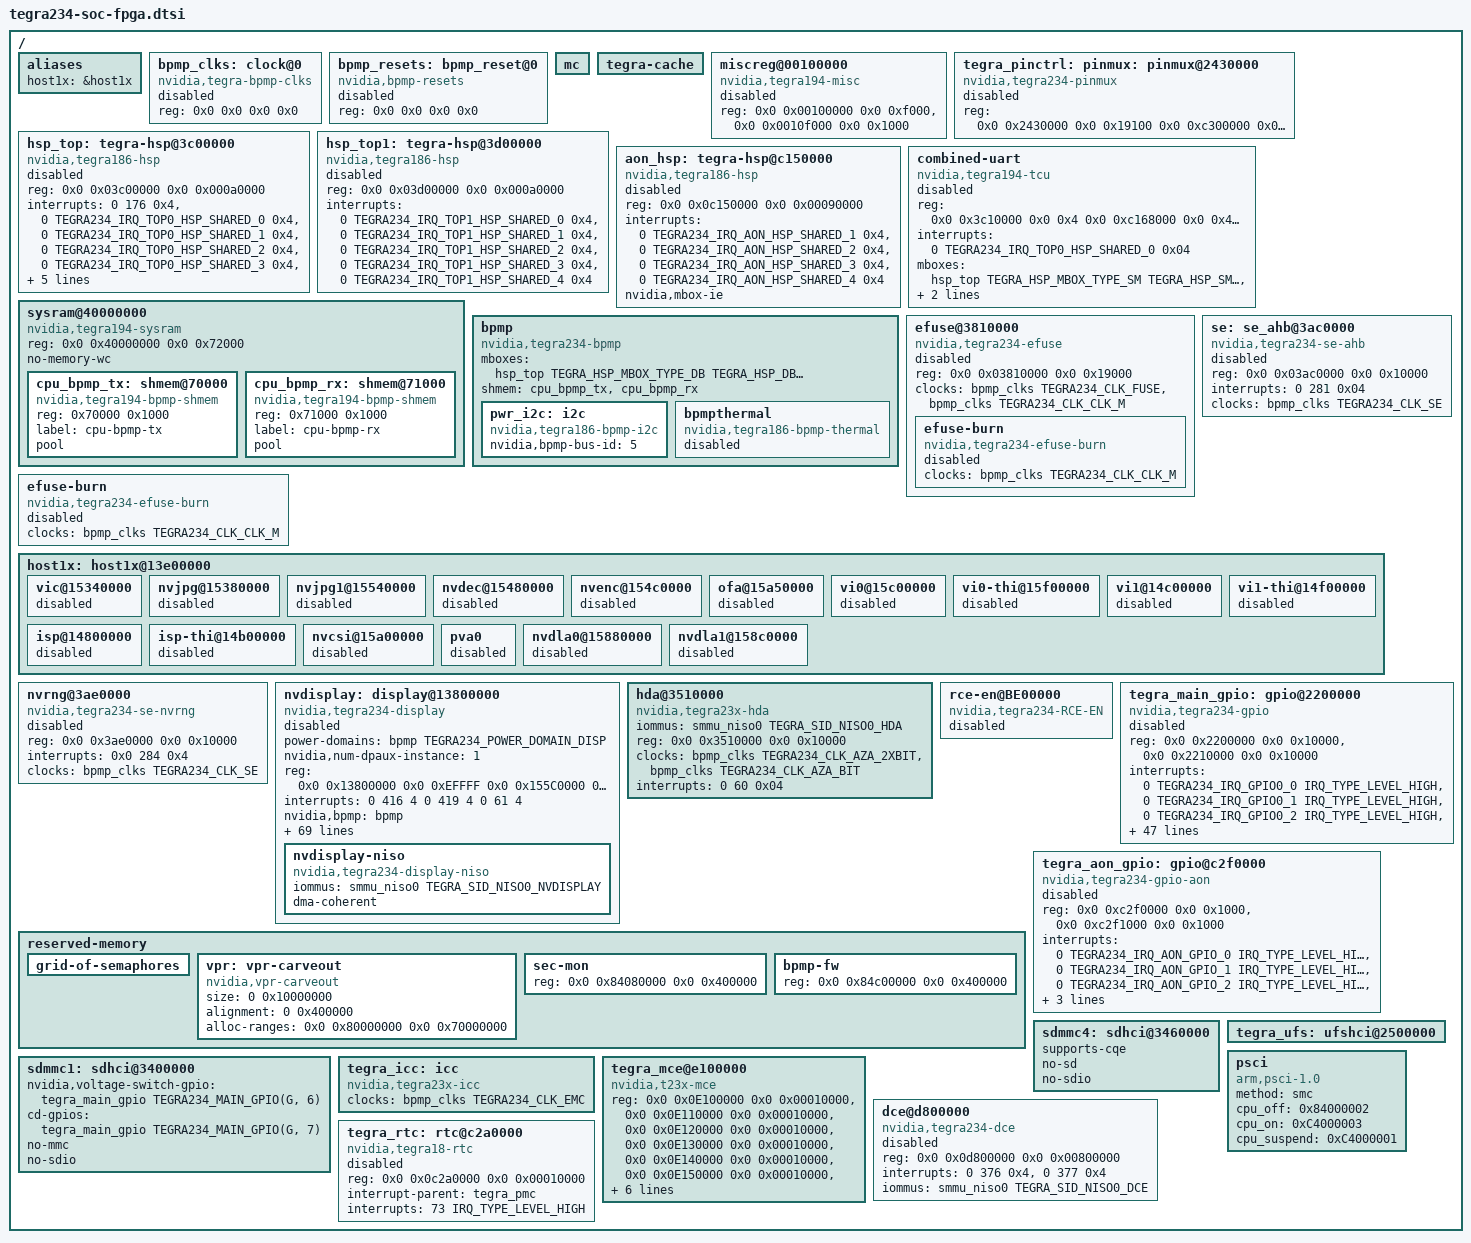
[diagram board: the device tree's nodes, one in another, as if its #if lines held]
/*
 * Copyright (c) 2019-2022, NVIDIA CORPORATION.  All rights reserved.
 *
 * This program is free software; you can redistribute it and/or modify it
 * under the terms and conditions of the GNU General Public License,
 * version 2, as published by the Free Software Foundation.
 *
 * This program is distributed in the hope it will be useful, but WITHOUT
 * ANY WARRANTY; without even the implied warranty of MERCHANTABILITY or
 * FITNESS FOR A PARTICULAR PURPOSE.  See the GNU General Public License for
 * more details.
 *
 * You should have received a copy of the GNU General Public License
 * along with this program.  If not, see <http://www.gnu.org/licenses/>.
 */

#include "tegra234-soc/tegra234-soc-minimal.dtsi"
#include <dt-bindings/memory/tegra234-smmu-streamid.h>
#include "tegra234-soc-cbb.dtsi"
#include "tegra234-soc/tegra234-soc-memory.dtsi"
#include "tegra234-soc-pcie-fpga.dtsi"
#include <dt-bindings/gpio/tegra234-gpio.h>
#include <dt-bindings/mailbox/tegra186-hsp.h>
#include "tegra234-soc-gpcdma.dtsi"
#include <dt-bindings/clock/tegra234-clock.h>
#include <dt-bindings/clock/tegra194-clock.h>
#include <dt-bindings/reset/tegra234-reset.h>
#include "dt-bindings/soc/tegra234-powergate.h"
#include "tegra234-soc/tegra234-soc-sdhci.dtsi"
#include "tegra234-soc-pmc.dtsi"
#include "tegra234-soc-uart.dtsi"
#include "tegra234-soc-i2c.dtsi"
#include "tegra234-soc-ufshc.dtsi"
#include "tegra234-soc-spi.dtsi"
#include "tegra234-psc.dtsi"
#include "tegra234-soc-host1x.dtsi"
#include "tegra234-aon.dtsi"
#include "tegra234-soc-coresight.dtsi"
#include <dt-bindings/interconnect/tegra_icc_id.h>

/ {
	aliases {
		host1x = &host1x;
	};

#if TEGRA_BPMP_FW_DT_VERSION <= DT_VERSION_1
	bpmp_clks: clock@0 {
		compatible = "nvidia,tegra-bpmp-clks";
		reg = <0x0 0x0 0x0 0x0>;
		#clock-cells = <1>;
		status = "disabled";
	};

	bpmp_resets: bpmp_reset@0 {
		compatible = "nvidia,bpmp-resets";
		reg = <0x0 0x0 0x0 0x0>;
		#reset-cells = <1>;
		status = "disabled";
	};
#endif

	mc {
		status = "okay";
	};

	/* L4 cache */
	tegra-cache {
		status = "okay";
	};

	miscreg@00100000 {
		compatible = "nvidia,tegra194-misc", "nvidia,tegra186-miscreg";
		reg = <0x0 0x00100000 0x0 0xf000>, /* Chipid */
		      <0x0 0x0010f000 0x0 0x1000>; /* Straps */
		status = "disabled";
	};

	tegra_pinctrl: pinmux: pinmux@2430000 {
		compatible = "nvidia,tegra234-pinmux";
		reg = <0x0 0x2430000 0x0 0x19100
			0x0 0xc300000 0x0 0x4000>;
		#gpio-range-cells = <3>;
		status = "disabled";
	};

	hsp_top: tegra-hsp@3c00000 {
		compatible = "nvidia,tegra186-hsp";
		reg = <0x0 0x03c00000 0x0 0x000a0000>;
		interrupts =	<0 176 0x4>,
				<0 TEGRA234_IRQ_TOP0_HSP_SHARED_0 0x4>,
				<0 TEGRA234_IRQ_TOP0_HSP_SHARED_1 0x4>,
				<0 TEGRA234_IRQ_TOP0_HSP_SHARED_2 0x4>,
				<0 TEGRA234_IRQ_TOP0_HSP_SHARED_3 0x4>,
				<0 TEGRA234_IRQ_TOP0_HSP_SHARED_4 0x4>,
				<0 TEGRA234_IRQ_TOP0_HSP_SHARED_5 0x4>,
				<0 TEGRA234_IRQ_TOP0_HSP_SHARED_6 0x4>,
				<0 TEGRA234_IRQ_TOP0_HSP_SHARED_7 0x4>;
		interrupt-names = "doorbell",
				"shared0", "shared1", "shared2", "shared3",
				"shared4", "shared5", "shared6", "shared7";
		#mbox-cells = <2>;
		nvidia,mbox-ie;
		status = "disabled";
	};

	hsp_top1: tegra-hsp@3d00000 {
		compatible = "nvidia,tegra186-hsp";
		reg = <0x0 0x03d00000 0x0 0x000a0000>;
		interrupts = <0 TEGRA234_IRQ_TOP1_HSP_SHARED_0 0x4>,
				<0 TEGRA234_IRQ_TOP1_HSP_SHARED_1 0x4>,
				<0 TEGRA234_IRQ_TOP1_HSP_SHARED_2 0x4>,
				<0 TEGRA234_IRQ_TOP1_HSP_SHARED_3 0x4>,
				<0 TEGRA234_IRQ_TOP1_HSP_SHARED_4 0x4>;
		interrupt-names = "shared0", "shared1", "shared2", "shared3", "shared4";
		#mbox-cells = <2>;
		status = "disabled";
	};

    aon_hsp: tegra-hsp@c150000 {
        compatible = "nvidia,tegra186-hsp";
        reg = <0x0 0x0c150000 0x0 0x00090000>;
        interrupts = <0 TEGRA234_IRQ_AON_HSP_SHARED_1 0x4>,
                <0 TEGRA234_IRQ_AON_HSP_SHARED_2 0x4>,
                <0 TEGRA234_IRQ_AON_HSP_SHARED_3 0x4>,
                <0 TEGRA234_IRQ_AON_HSP_SHARED_4 0x4>;
        interrupt-names = "shared1", "shared2", "shared3", "shared4";
        #mbox-cells = <2>;
        nvidia,mbox-ie;
        status = "disabled";
    };

    combined-uart {
        compatible = "nvidia,tegra194-tcu";
        reg = <0x0 0x3c10000 0x0 0x4   /* TOP0_HSP_SM_0_1_BASE */
               0x0 0xc168000 0x0 0x4       /* AON_HSP_SM_1_BASE */
               0x0 0x3c00000 0x0 0x1000>; /* TOP0_HSP_COMMON_BASE */
        interrupts = <0 TEGRA234_IRQ_TOP0_HSP_SHARED_0 0x04>;
        mboxes = <&hsp_top TEGRA_HSP_MBOX_TYPE_SM TEGRA_HSP_SM_RX(0)>,
            <&aon_hsp TEGRA_HSP_MBOX_TYPE_SM TEGRA_HSP_SM_TX(1)>;
        mbox-names = "rx", "tx";
        status = "disabled";
    };

#if TEGRA_BPMP_FW_DT_VERSION >= DT_VERSION_2
	sysram@40000000 {
		compatible = "nvidia,tegra194-sysram", "mmio-sram";
		reg = <0x0 0x40000000 0x0 0x72000>;
		#address-cells = <1>;
		#size-cells = <1>;
		ranges = <0x0 0x0 0x40000000 0x72000>;
		no-memory-wc;

		cpu_bpmp_tx: shmem@70000 {
			compatible = "nvidia,tegra194-bpmp-shmem";
			reg = <0x70000 0x1000>;
			label = "cpu-bpmp-tx";
			pool;
		};

		cpu_bpmp_rx: shmem@71000 {
			compatible = "nvidia,tegra194-bpmp-shmem";
			reg = <0x71000 0x1000>;
			label = "cpu-bpmp-rx";
			pool;
		};
	};

	bpmp: bpmp {
		compatible = "nvidia,tegra234-bpmp", "nvidia,tegra186-bpmp";
		mboxes = <&hsp_top TEGRA_HSP_MBOX_TYPE_DB
				   TEGRA_HSP_DB_MASTER_BPMP>;
		shmem = <&cpu_bpmp_tx &cpu_bpmp_rx>;
		#clock-cells = <1>;
		#reset-cells = <1>;
		#power-domain-cells = <1>;

		pwr_i2c: i2c {
			compatible = "nvidia,tegra186-bpmp-i2c";
			nvidia,bpmp-bus-id = <5>;
			#address-cells = <1>;
			#size-cells = <0>;
		};

		bpmpthermal {
			compatible = "nvidia,tegra186-bpmp-thermal";
			#thermal-sensor-cells = <1>;
			status = "disabled";
		};
	};
#else
	bpmp: bpmp {
		compatible = "nvidia,tegra186-bpmp";
		iommus = <&smmu_niso1 TEGRA_SID_NISO1_BPMP>;
		dma-coherent;
		reg = <0x0 0x0d000000 0x0 0x00800000>,
		      <0x0 0x40070000 0x0 0x00001000>,
		      <0x0 0x40071000 0x0 0x00001000>;
		status = "disabled";
		#power-domain-cells = <1>;
		#strap-cells = <1>;
		#nvidia,controller-id-cells = <1>;

		bpmpthermal {
			compatible = "nvidia,tegra186-bpmp-thermal";
			#thermal-sensor-cells = <1>;
			status = "disabled";
		};
	};
#endif

	efuse@3810000 {
		compatible = "nvidia,tegra234-efuse";
		reg = <0x0 0x03810000 0x0 0x19000>;
		clocks = <&bpmp_clks TEGRA234_CLK_FUSE>,
		         <&bpmp_clks TEGRA234_CLK_CLK_M>;
		clock-names = "fuse", "clk_m";
		status = "disabled";
#if LINUX_VERSION < 419
		efuse-burn {
			compatible = "nvidia,tegra234-efuse-burn";
			clocks = <&bpmp_clks TEGRA234_CLK_CLK_M>;
			clock-names = "clk_m";
			status = "disabled";
		};
#endif
	};
#if LINUX_VERSION >= 419
	efuse-burn {
		compatible = "nvidia,tegra234-efuse-burn";
		clocks = <&bpmp_clks TEGRA234_CLK_CLK_M>;
		clock-names = "clk_m";
		status = "disabled";
	};
#endif

	se: se_ahb@3ac0000 {
		compatible = "nvidia,tegra234-se-ahb";
		reg = <0x0 0x03ac0000 0x0 0x10000>;
		interrupts = <0 281 0x04>;
		clocks = <&bpmp_clks TEGRA234_CLK_SE>;
		clock-names = "se";
		status = "disabled";
	};

	host1x: host1x@13e00000 {

		vic@15340000 {
			status = "disabled";
		};

		nvjpg@15380000 {
			status = "disabled";
		};

		nvjpg1@15540000 {
			status = "disabled";
		};

		nvdec@15480000 {
			status = "disabled";
		};

		nvenc@154c0000 {
			status = "disabled";
		};

		ofa@15a50000 {
			status = "disabled";
		};

		vi0@15c00000 {
			status = "disabled";
		};

		vi0-thi@15f00000 {
			status = "disabled";
		};

		vi1@14c00000 {
			status = "disabled";
		};

		vi1-thi@14f00000 {
			status = "disabled";
		};

		isp@14800000 {
			status = "disabled";
		};

		isp-thi@14b00000 {
			status = "disabled";
		};

		nvcsi@15a00000 {
			status = "disabled";
		};

		pva0 {
			status = "disabled";
		};

		nvdla0@15880000 {
			status = "disabled";
		};

		nvdla1@158c0000 {
			status = "disabled";
		};
	};

	nvrng@3ae0000 {
		compatible = "nvidia,tegra234-se-nvrng";
		reg = <0x0 0x3ae0000 0x0 0x10000>;
		interrupts = <0x0 284 0x4>;
		clocks = <&bpmp_clks TEGRA234_CLK_SE>;
		clock-names = "se";
		status = "disabled";
	};

	nvdisplay: display@13800000 {
		compatible = "nvidia,tegra234-display";
		power-domains = <&bpmp TEGRA234_POWER_DOMAIN_DISP>;
		nvidia,num-dpaux-instance = <1>;
		reg-names = "nvdisplay", "dpaux0", "hdacodec";
		reg = <0x0 0x13800000 0x0 0xEFFFF    /* nvdisplay */
		       0x0 0x155C0000 0x0 0xFFFF     /* dpaux0 */
		       0x0 0x0242c000 0x0 0x1000>;   /* hdacodec */
		interrupt-names = "nvdisplay", "dpaux0", "hdacodec";
		interrupts = <0 416 4
			      0 419 4
			      0  61 4>;
		nvidia,bpmp = <&bpmp>;
		clocks = <&bpmp_clks TEGRA234_CLK_HUB>,
			 <&bpmp_clks TEGRA234_CLK_DISP>,
			 <&bpmp_clks TEGRA234_CLK_NVDISPLAY_P0>,
			 <&bpmp_clks TEGRA234_CLK_NVDISPLAY_P1>,
			 <&bpmp_clks TEGRA234_CLK_DPAUX>,
			 <&bpmp_clks TEGRA234_CLK_FUSE>,
			 <&bpmp_clks TEGRA234_CLK_DSIPLL_VCO>,
			 <&bpmp_clks TEGRA234_CLK_DSIPLL_CLKOUTPN>,
			 <&bpmp_clks TEGRA234_CLK_DSIPLL_CLKOUTA>,
			 <&bpmp_clks TEGRA234_CLK_SPPLL0_VCO>,
			 <&bpmp_clks TEGRA234_CLK_SPPLL0_CLKOUTPN>,
			 <&bpmp_clks TEGRA234_CLK_SPPLL0_CLKOUTA>,
			 <&bpmp_clks TEGRA234_CLK_SPPLL0_CLKOUTB>,
			 <&bpmp_clks TEGRA234_CLK_SPPLL0_DIV10>,
			 <&bpmp_clks TEGRA234_CLK_SPPLL0_DIV25>,
			 <&bpmp_clks TEGRA234_CLK_SPPLL0_DIV27PN>,
			 <&bpmp_clks TEGRA234_CLK_SPPLL1_VCO>,
			 <&bpmp_clks TEGRA234_CLK_SPPLL1_CLKOUTPN>,
			 <&bpmp_clks TEGRA234_CLK_SPPLL1_DIV27PN>,
			 <&bpmp_clks TEGRA234_CLK_VPLL0_REF>,
			 <&bpmp_clks TEGRA234_CLK_VPLL0>,
			 <&bpmp_clks TEGRA234_CLK_VPLL1>,
			 <&bpmp_clks TEGRA234_CLK_NVDISPLAY_P0_REF>,
			 <&bpmp_clks TEGRA234_CLK_RG0>,
			 <&bpmp_clks TEGRA234_CLK_RG1>,
			 <&bpmp_clks TEGRA234_CLK_DISPPLL>,
			 <&bpmp_clks TEGRA234_CLK_DISPHUBPLL>,
			 <&bpmp_clks TEGRA234_CLK_DSI_LP>,
			 <&bpmp_clks TEGRA234_CLK_DSI_CORE>,
			 <&bpmp_clks TEGRA234_CLK_DSI_PIXEL>,
			 <&bpmp_clks TEGRA234_CLK_PRE_SOR0>,
			 <&bpmp_clks TEGRA234_CLK_PRE_SOR1>,
			 <&bpmp_clks TEGRA234_CLK_DP_LINK_REF>,
			 <&bpmp_clks TEGRA234_CLK_SOR_LINKA_INPUT>,
			 <&bpmp_clks TEGRA234_CLK_SOR_LINKA_AFIFO>,
			 <&bpmp_clks TEGRA234_CLK_SOR_LINKA_AFIFO_M>,
			 <&bpmp_clks TEGRA234_CLK_RG0_M>,
			 <&bpmp_clks TEGRA234_CLK_RG1_M>,
			 <&bpmp_clks TEGRA234_CLK_SOR0_M>,
			 <&bpmp_clks TEGRA234_CLK_SOR1_M>,
			 <&bpmp_clks TEGRA234_CLK_PLLHUB>,
			 <&bpmp_clks TEGRA234_CLK_SOR0>,
			 <&bpmp_clks TEGRA234_CLK_SOR1>,
			 <&bpmp_clks TEGRA234_CLK_SOR_PAD_INPUT>,
			 <&bpmp_clks TEGRA234_CLK_PRE_SF0>,
			 <&bpmp_clks TEGRA234_CLK_SF0>,
			 <&bpmp_clks TEGRA234_CLK_SF1>,
			 <&bpmp_clks TEGRA234_CLK_DSI_PAD_INPUT>,
			 <&bpmp_clks TEGRA234_CLK_PRE_SOR0_REF>,
			 <&bpmp_clks TEGRA234_CLK_PRE_SOR1_REF>,
			 <&bpmp_clks TEGRA234_CLK_SOR0_PLL_REF>,
			 <&bpmp_clks TEGRA234_CLK_SOR1_PLL_REF>,
			 <&bpmp_clks TEGRA234_CLK_SOR0_REF>,
			 <&bpmp_clks TEGRA234_CLK_SOR1_REF>,
			 <&bpmp_clks TEGRA234_CLK_OSC>,
			 <&bpmp_clks TEGRA234_CLK_DSC>,
			 <&bpmp_clks TEGRA234_CLK_MAUD>,
			 <&bpmp_clks TEGRA234_CLK_AZA_2XBIT>,
			 <&bpmp_clks TEGRA234_CLK_AZA_BIT>,
			 <&bpmp_clks TEGRA234_CLK_MIPI_CAL>,
			 <&bpmp_clks TEGRA234_CLK_UART_FST_MIPI_CAL>,
			 <&bpmp_clks TEGRA234_CLK_SOR0_DIV>;
		clock-names = "nvdisplayhub_clk",
			      "nvdisplay_disp_clk",
			      "nvdisplay_p0_clk",
			      "nvdisplay_p1_clk",
			      "dpaux0_clk",
			      "fuse_clk",
			      "dsipll_vco_clk",
			      "dsipll_clkoutpn_clk",
			      "dsipll_clkouta_clk",
			      "sppll0_vco_clk",
			      "sppll0_clkoutpn_clk",
			      "sppll0_clkouta_clk",
			      "sppll0_clkoutb_clk",
			      "sppll0_div10_clk",
			      "sppll0_div25_clk",
			      "sppll0_div27_clk",
			      "sppll1_vco_clk",
			      "sppll1_clkoutpn_clk",
			      "sppll1_div27_clk",
			      "vpll0_ref_clk",
			      "vpll0_clk",
			      "vpll1_clk",
			      "nvdisplay_p0_ref_clk",
			      "rg0_clk",
			      "rg1_clk",
			      "disppll_clk",
			      "disphubpll_clk",
			      "dsi_lp_clk",
			      "dsi_core_clk",
			      "dsi_pixel_clk",
			      "pre_sor0_clk",
			      "pre_sor1_clk",
			      "dp_link_ref_clk",
			      "sor_linka_input_clk",
			      "sor_linka_afifo_clk",
			      "sor_linka_afifo_m_clk",
			      "rg0_m_clk",
			      "rg1_m_clk",
			      "sor0_m_clk",
			      "sor1_m_clk",
			      "pllhub_clk",
			      "sor0_clk",
			      "sor1_clk",
			      "sor_pad_input_clk",
			      "pre_sf0_clk",
			      "sf0_clk",
			      "sf1_clk",
			      "dsi_pad_input_clk",
			      "pre_sor0_ref_clk",
			      "pre_sor1_ref_clk",
			      "sor0_ref_pll_clk",
			      "sor1_ref_pll_clk",
			      "sor0_ref_clk",
			      "sor1_ref_clk",
			      "osc_clk",
			      "dsc_clk",
			      "maud_clk",
			      "aza_2xbit_clk",
			      "aza_bit_clk",
			      "mipi_cal_clk",
			      "uart_fst_mipi_cal_clk",
			      "sor0_div_clk";
		resets = <&bpmp_resets TEGRA234_RESET_NVDISPLAY>,
			 <&bpmp_resets TEGRA234_RESET_DPAUX>,
			 <&bpmp_resets TEGRA234_RESET_HDACODEC>,
			 <&bpmp_resets TEGRA234_RESET_DSI_CORE>,
			 <&bpmp_resets TEGRA234_RESET_MIPI_CAL>;
		reset-names = "nvdisplay_reset",
			      "dpaux0_reset",
			      "hdacodec_reset",
			      "dsi_core_reset",
			      "mipi_cal_reset";
		status = "disabled";
		iommus = <&smmu_iso TEGRA_SID_ISO_NVDISPLAY>;
		non-coherent;
		nvdisplay-niso {
			compatible = "nvidia,tegra234-display-niso";
			iommus = <&smmu_niso0 TEGRA_SID_NISO0_NVDISPLAY>;
			dma-coherent;
		};
	};

        hda@3510000 {
                compatible = "nvidia,tegra23x-hda";
                iommus = <&smmu_niso0 TEGRA_SID_NISO0_HDA>;
                reg = <0x0 0x3510000 0x0 0x10000>;
                clocks = <&bpmp_clks TEGRA234_CLK_AZA_2XBIT>,
                         <&bpmp_clks TEGRA234_CLK_AZA_BIT>;
		clock-names = "hda", "hda2codec_2x";
                interrupts = <0 60 0x04>;
                status = "okay";
        };

	rce-en@BE00000 {
		compatible = "nvidia,tegra234-RCE-EN";
		status = "disabled";
	};

        reserved-memory {
                grid-of-semaphores {
                        /delete-property/ cvdevs;
                };

		vpr: vpr-carveout {
				compatible = "nvidia,vpr-carveout";
				size = <0 0x10000000>;
				alignment = <0 0x400000>;
				alloc-ranges = <0x0 0x80000000 0x0 0x70000000>;
		};

		/* The sec-mon memory in bootwrapper */
		sec-mon {
			reg = <0x0 0x84080000 0x0 0x400000>;
		};

		bpmp-fw {
                        reg = <0x0 0x84c00000 0x0 0x400000>;
                };
        };

	tegra_main_gpio: gpio@2200000 {
		compatible = "nvidia,tegra234-gpio";
		reg-names = "security", "gpio";
		reg =	<0x0 0x2200000 0x0 0x10000>,
			<0x0 0x2210000 0x0 0x10000>;
		interrupts =
			<0 TEGRA234_IRQ_GPIO0_0 IRQ_TYPE_LEVEL_HIGH>,
			<0 TEGRA234_IRQ_GPIO0_1 IRQ_TYPE_LEVEL_HIGH>,
			<0 TEGRA234_IRQ_GPIO0_2 IRQ_TYPE_LEVEL_HIGH>,
			<0 TEGRA234_IRQ_GPIO0_3 IRQ_TYPE_LEVEL_HIGH>,
			<0 TEGRA234_IRQ_GPIO0_4 IRQ_TYPE_LEVEL_HIGH>,
			<0 TEGRA234_IRQ_GPIO0_5 IRQ_TYPE_LEVEL_HIGH>,
			<0 TEGRA234_IRQ_GPIO0_6 IRQ_TYPE_LEVEL_HIGH>,
			<0 TEGRA234_IRQ_GPIO0_7 IRQ_TYPE_LEVEL_HIGH>,
			<0 TEGRA234_IRQ_GPIO1_0 IRQ_TYPE_LEVEL_HIGH>,
			<0 TEGRA234_IRQ_GPIO1_1 IRQ_TYPE_LEVEL_HIGH>,
			<0 TEGRA234_IRQ_GPIO1_2 IRQ_TYPE_LEVEL_HIGH>,
			<0 TEGRA234_IRQ_GPIO1_3 IRQ_TYPE_LEVEL_HIGH>,
			<0 TEGRA234_IRQ_GPIO1_4 IRQ_TYPE_LEVEL_HIGH>,
			<0 TEGRA234_IRQ_GPIO1_5 IRQ_TYPE_LEVEL_HIGH>,
			<0 TEGRA234_IRQ_GPIO1_6 IRQ_TYPE_LEVEL_HIGH>,
			<0 TEGRA234_IRQ_GPIO1_7 IRQ_TYPE_LEVEL_HIGH>,
			<0 TEGRA234_IRQ_GPIO2_0 IRQ_TYPE_LEVEL_HIGH>,
			<0 TEGRA234_IRQ_GPIO2_1 IRQ_TYPE_LEVEL_HIGH>,
			<0 TEGRA234_IRQ_GPIO2_2 IRQ_TYPE_LEVEL_HIGH>,
			<0 TEGRA234_IRQ_GPIO2_3 IRQ_TYPE_LEVEL_HIGH>,
			<0 TEGRA234_IRQ_GPIO2_4 IRQ_TYPE_LEVEL_HIGH>,
			<0 TEGRA234_IRQ_GPIO2_5 IRQ_TYPE_LEVEL_HIGH>,
			<0 TEGRA234_IRQ_GPIO2_6 IRQ_TYPE_LEVEL_HIGH>,
			<0 TEGRA234_IRQ_GPIO2_7 IRQ_TYPE_LEVEL_HIGH>,
			<0 TEGRA234_IRQ_GPIO3_0 IRQ_TYPE_LEVEL_HIGH>,
			<0 TEGRA234_IRQ_GPIO3_1 IRQ_TYPE_LEVEL_HIGH>,
			<0 TEGRA234_IRQ_GPIO3_2 IRQ_TYPE_LEVEL_HIGH>,
			<0 TEGRA234_IRQ_GPIO3_3 IRQ_TYPE_LEVEL_HIGH>,
			<0 TEGRA234_IRQ_GPIO3_4 IRQ_TYPE_LEVEL_HIGH>,
			<0 TEGRA234_IRQ_GPIO3_5 IRQ_TYPE_LEVEL_HIGH>,
			<0 TEGRA234_IRQ_GPIO3_6 IRQ_TYPE_LEVEL_HIGH>,
			<0 TEGRA234_IRQ_GPIO3_7 IRQ_TYPE_LEVEL_HIGH>,
			<0 TEGRA234_IRQ_GPIO4_0 IRQ_TYPE_LEVEL_HIGH>,
			<0 TEGRA234_IRQ_GPIO4_1 IRQ_TYPE_LEVEL_HIGH>,
			<0 TEGRA234_IRQ_GPIO4_2 IRQ_TYPE_LEVEL_HIGH>,
			<0 TEGRA234_IRQ_GPIO4_3 IRQ_TYPE_LEVEL_HIGH>,
			<0 TEGRA234_IRQ_GPIO4_4 IRQ_TYPE_LEVEL_HIGH>,
			<0 TEGRA234_IRQ_GPIO4_5 IRQ_TYPE_LEVEL_HIGH>,
			<0 TEGRA234_IRQ_GPIO4_6 IRQ_TYPE_LEVEL_HIGH>,
			<0 TEGRA234_IRQ_GPIO4_7 IRQ_TYPE_LEVEL_HIGH>,
			<0 TEGRA234_IRQ_GPIO5_0 IRQ_TYPE_LEVEL_HIGH>,
			<0 TEGRA234_IRQ_GPIO5_1 IRQ_TYPE_LEVEL_HIGH>,
			<0 TEGRA234_IRQ_GPIO5_2 IRQ_TYPE_LEVEL_HIGH>,
			<0 TEGRA234_IRQ_GPIO5_3 IRQ_TYPE_LEVEL_HIGH>,
			<0 TEGRA234_IRQ_GPIO5_4 IRQ_TYPE_LEVEL_HIGH>,
			<0 TEGRA234_IRQ_GPIO5_5 IRQ_TYPE_LEVEL_HIGH>,
			<0 TEGRA234_IRQ_GPIO5_6 IRQ_TYPE_LEVEL_HIGH>,
			<0 TEGRA234_IRQ_GPIO5_7 IRQ_TYPE_LEVEL_HIGH>;
		gpio-controller;
		#gpio-cells = <2>;
		interrupt-controller;
		#interrupt-cells = <2>;
		status = "disabled";
	};

	tegra_aon_gpio: gpio@c2f0000 {
		compatible = "nvidia,tegra234-gpio-aon";
		reg-names = "security", "gpio";
		reg = 	<0x0 0xc2f0000 0x0 0x1000>,
			<0x0 0xc2f1000 0x0 0x1000>;
		interrupts =
			<0 TEGRA234_IRQ_AON_GPIO_0 IRQ_TYPE_LEVEL_HIGH>,
			<0 TEGRA234_IRQ_AON_GPIO_1 IRQ_TYPE_LEVEL_HIGH>,
			<0 TEGRA234_IRQ_AON_GPIO_2 IRQ_TYPE_LEVEL_HIGH>,
			<0 TEGRA234_IRQ_AON_GPIO_3 IRQ_TYPE_LEVEL_HIGH>;
		gpio-controller;
		#gpio-cells = <2>;
		interrupt-controller;
		#interrupt-cells = <2>;
		status = "disabled";
        };

	sdmmc4: sdhci@3460000 { /* Used for eMMC */
#if TEGRA_IOMMU_DT_VERSION >= DT_VERSION_2
		supports-cqe;
#endif
		no-sd;
		no-sdio;
		status = "okay";
	};

	sdmmc1: sdhci@3400000 {
		/delete-property/ pinctrl-names;
		/delete-property/ pinctrl-0;
		/delete-property/ pinctrl-1;
		nvidia,voltage-switch-gpio = <&tegra_main_gpio TEGRA234_MAIN_GPIO(G, 6) 0>;
		cd-gpios = <&tegra_main_gpio TEGRA234_MAIN_GPIO(G, 7) 0>;
		no-mmc;
		no-sdio;
		status = "okay";
	 };

	 tegra_ufs: ufshci@2500000 {
		status = "okay";
	};

	tegra_icc: icc {
		#interconnect-cells = <1>;
		clocks = <&bpmp_clks TEGRA234_CLK_EMC>;
		clock-names = "emc";
		compatible = "nvidia,tegra23x-icc";
		status = "okay";
	};

	tegra_mce@e100000 {
		compatible = "nvidia,t23x-mce";
		reg =   <0x0 0x0E100000 0x0 0x00010000>, /* ARI BASE Core 0*/
			<0x0 0x0E110000 0x0 0x00010000>,
			<0x0 0x0E120000 0x0 0x00010000>,
			<0x0 0x0E130000 0x0 0x00010000>,
			<0x0 0x0E140000 0x0 0x00010000>,
			<0x0 0x0E150000 0x0 0x00010000>,
			<0x0 0x0E160000 0x0 0x00010000>,
			<0x0 0x0E170000 0x0 0x00010000>,
			<0x0 0x0E180000 0x0 0x00010000>,
			<0x0 0x0E190000 0x0 0x00010000>,
			<0x0 0x0E1A0000 0x0 0x00010000>,
			<0x0 0x0E1B0000 0x0 0x00010000>;
		status = "okay";
	};

	psci {
		compatible = "arm,psci-1.0";
		method = "smc";
		cpu_off = <0x84000002>;
		cpu_on = <0xC4000003>;
		cpu_suspend = <0xC4000001>;
		status = "okay";
	};

	dce@d800000 {
		compatible = "nvidia,tegra234-dce";
		reg = <0x0 0x0d800000 0x0 0x00800000>;
		interrupts = <0 376 0x4>, <0 377 0x4>;
		interrupt-names = "wdt-remote", "dce-sm0";
		iommus = <&smmu_niso0 TEGRA_SID_NISO0_DCE>;
		status = "disabled";
	};

	tegra_rtc: rtc@c2a0000 {
		compatible = "nvidia,tegra18-rtc";
		reg = <0x0 0x0c2a0000 0x0 0x00010000>;
		interrupt-parent = <&tegra_pmc>;
		interrupts = <73 IRQ_TYPE_LEVEL_HIGH>;
		status = "disabled";
	};
};

